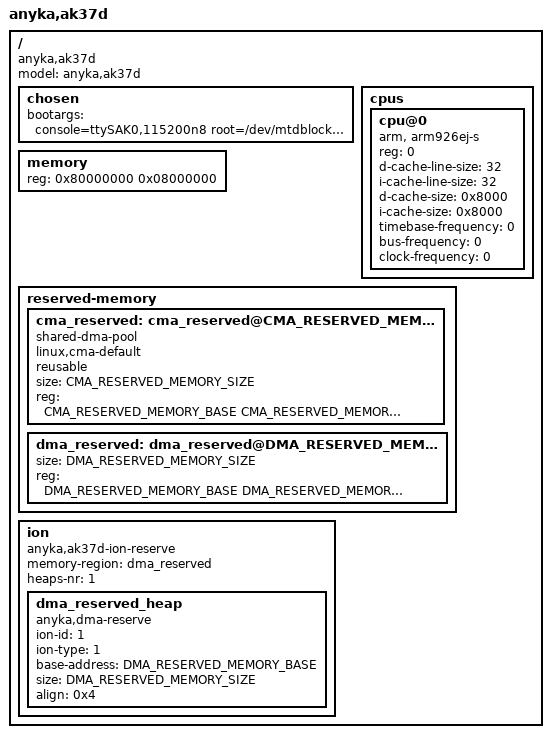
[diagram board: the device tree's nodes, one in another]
/*
 * AK37D 128M memory chip dts
 *
 * Copyright (C) 2018 Anyka(Guangzhou) Microelectronics Technology Co., Ltd.
 *
 * Author: Feilong Dong <dong_feilong@anyka.com>
 *
 * This program is free software; you can redistribute it and/or modify
 * it under the terms of the GNU General Public License as published by
 * the Free Software Foundation; either version 2 of the License, or
 * (at your option) any later version.
 *
 * This program is distributed in the hope that it will be useful,
 * but WITHOUT ANY WARRANTY; without even the implied warranty of
 * MERCHANTABILITY or FITNESS FOR A PARTICULAR PURPOSE.  See the
 * GNU General Public License for more details.
 */

#include "anycloud_ak37d_common.dtsi"

#define CMA_RESERVED_MEMORY_BASE  0x85C00000
#define CMA_RESERVED_MEMORY_SIZE  0xc00000
#define DMA_RESERVED_MEMORY_BASE  0x81400000
#define DMA_RESERVED_MEMORY_SIZE  0x4800000
/ {
    model = "anyka,ak37d";
    compatible = "anyka,ak37d","anyka,ak3918ev501","anyka,ak3751d","anyka,ak3761d";

	chosen {
		/* No padding required - the uboot can do that. */
		//bootargs = "console=ttySAK0,115200";
		bootargs = "console=ttySAK0,115200n8 root=/dev/mtdblock6 rootfstype=squashfs init=/sbin/init mem=128M memsize=128M";
	};

	cpus {
	    #address-cells = <1>;
	    #size-cells = <0>;

	    cpu@0 {
	        compatible = "arm, arm926ej-s";
	        device_type = "cpu";
	        reg = <0>;
	        d-cache-line-size = <32>;  // 32 bytes
	        i-cache-line-size = <32>;  // 32 bytes
	        d-cache-size = <0x8000>;
	        i-cache-size = <0x8000>;
	        timebase-frequency = <0>;
	        bus-frequency = <0>;
	        clock-frequency = <0>;
	    };
	};

    memory {
	    device_type = "memory";
	    reg = <0x80000000 0x08000000>;
	};

    reserved-memory {
        #address-cells = <1>;
        #size-cells = <1>;
        ranges;
        cma_reserved: cma_reserved@CMA_RESERVED_MEMORY_BASE {
            compatible = "shared-dma-pool";
            linux,cma-default;
            reusable;
            size = <CMA_RESERVED_MEMORY_SIZE>;
            reg = <CMA_RESERVED_MEMORY_BASE CMA_RESERVED_MEMORY_SIZE>;
            status = "okay";
        };

        dma_reserved: dma_reserved@DMA_RESERVED_MEMORY_BASE {
            /*compatible = "shared-dma-pool";*/
            /*linux,cma-default;*/
            /*reusable;*/
            size = <DMA_RESERVED_MEMORY_SIZE>;
            reg = <DMA_RESERVED_MEMORY_BASE DMA_RESERVED_MEMORY_SIZE>;
            status = "okay";
        };
    };

    ion {
        compatible = "anyka,ak37d-ion-reserve";
        memory-region = <&dma_reserved>;
        #address-cells = <1>;
        #size-cells = <1>;
        heaps-nr = <1>;
        ranges;

        dma_reserved_heap: dma_reserved_heap {
            compatible = "anyka,dma-reserve";
            ion-id = <1>;
            /* ion-type: 0 = cma ; 1 = prereserved memory which kernel do not  aware of */
            ion-type = <1>;
            base-address = <DMA_RESERVED_MEMORY_BASE>;
            size = <DMA_RESERVED_MEMORY_SIZE>;
            align = <0x4>;
            status = "okay";
        };
    };
};
